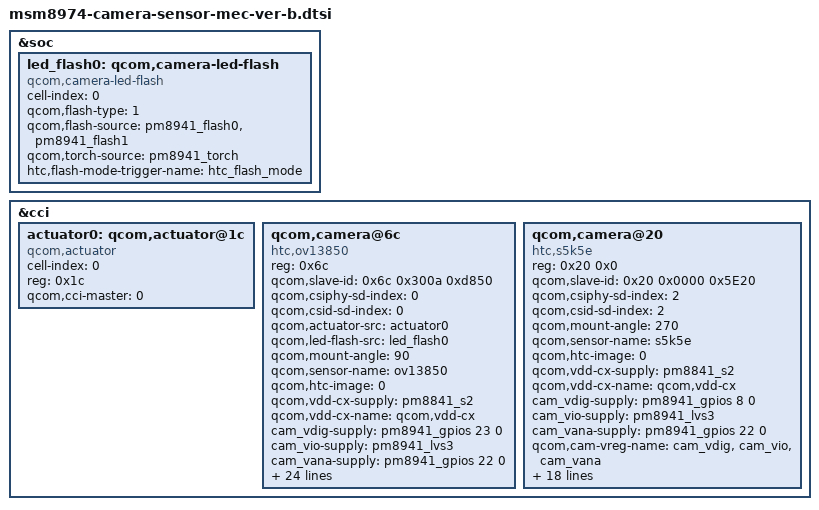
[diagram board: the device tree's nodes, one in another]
/*
 * Copyright (c) 2012-2013, The Linux Foundation. All rights reserved.
 *
 * This program is free software; you can redistribute it and/or modify
 * it under the terms of the GNU General Public License version 2 and
 * only version 2 as published by the Free Software Foundation.
 *
 * This program is distributed in the hope that it will be useful,
 * but WITHOUT ANY WARRANTY; without even the implied warranty of
 * MERCHANTABILITY or FITNESS FOR A PARTICULAR PURPOSE.  See the
 * GNU General Public License for more details.
 */

&soc {

	led_flash0: qcom,camera-led-flash {
		cell-index = <0>;
		compatible = "qcom,camera-led-flash";
		qcom,flash-type = <1>;
		qcom,flash-source = <&pm8941_flash0 &pm8941_flash1>;
		qcom,torch-source = <&pm8941_torch>;
                htc,flash-mode-trigger-name = "htc_flash_mode";
	};
};

&cci {
	actuator0: qcom,actuator@1c {
		cell-index = <0>;
		reg = <0x1c>;
		compatible = "qcom,actuator";
		qcom,cci-master = <0>;
	};

	qcom,camera@6c {
		compatible = "htc,ov13850";
		reg = <0x6c>;
		qcom,slave-id = <0x6c 0x300a 0xd850>;
		qcom,csiphy-sd-index = <0>;
		qcom,csid-sd-index = <0>;
		qcom,actuator-src = <&actuator0>;
		qcom,led-flash-src = <&led_flash0>;

		qcom,mount-angle = <90>;
		qcom,sensor-name = "ov13850";
		qcom,htc-image = <0>;
		qcom,vdd-cx-supply = <&pm8841_s2>;
		qcom,vdd-cx-name = "qcom,vdd-cx";
		cam_vdig-supply = <&pm8941_gpios 23 0>;
		cam_vio-supply = <&pm8941_lvs3>;
		cam_vana-supply = <&pm8941_gpios 22 0>;
		cam_vaf-supply = <&msmgpio 90 0>;
		qcom,cam-vreg-name = "cam_vdig", "cam_vio", "cam_vana",
				     "cam_vaf";
		qcom,cam-vreg-type = <2 1 2 2>;
		qcom,cam-vreg-min-voltage = <0 0 0 0>;
		qcom,cam-vreg-max-voltage = <0 0 0 0>;
		qcom,cam-vreg-op-mode = <0 100000 0 0>;
		qcom,cam-vreg-gpios-index = <2 99 5 3>;

		qcom,gpio-no-mux = <0>;
		gpios = <&msmgpio 15 0>,
			<&pm8941_gpios 12 0>,
			<&pm8941_gpios 23 0>,
			<&msmgpio 90 0>,
			<&pm8941_gpios 11 0>,
			<&pm8941_gpios 22 0>;

		qcom,gpio-reset = <1>;
		qcom,gpio-vcm-pwd = <4>;
		qcom,gpio-req-tbl-num = <0 1 2 3 4 5>;
		qcom,gpio-req-tbl-flags = <0 0 0 0 0 0>;
		qcom,gpio-req-tbl-label = "MCLK_CPU",
					  "CAM_PWDN",
					  "V_CAM_D1V2_EN",
					  "CAM_VCM2V85_EN",
					  "VCM_PWD",
					  "CAM_A2V9_EN";

		qcom,csi-lane-assign = <0x4320>;
		qcom,csi-lane-mask = <0x1F>;
		qcom,sensor-position = <0>;
		qcom,sensor-mode = <1>;
		qcom,cci-master = <0>;
		status = "ok";
	};

	qcom,camera@20 {
		compatible = "htc,s5k5e";
		reg = <0x20 0x0>;
		qcom,slave-id = <0x20 0x0000 0x5E20>;
		qcom,csiphy-sd-index = <2>;
		qcom,csid-sd-index = <2>;
		qcom,mount-angle = <270>;
		qcom,sensor-name = "s5k5e";
		qcom,htc-image = <0>;
		qcom,vdd-cx-supply = <&pm8841_s2>;
		qcom,vdd-cx-name = "qcom,vdd-cx";
		cam_vdig-supply = <&pm8941_gpios 8 0>;
		cam_vio-supply = <&pm8941_lvs3>;
		cam_vana-supply = <&pm8941_gpios 22 0>;

		qcom,cam-vreg-name = "cam_vdig", "cam_vio", "cam_vana";
		qcom,cam-vreg-type = <2 1 2>;
		qcom,cam-vreg-min-voltage = <0 0 0>;
		qcom,cam-vreg-max-voltage = <0 0 0>;
		qcom,cam-vreg-op-mode = <0 0 0>;
		qcom,cam-vreg-gpios-index = <2 99 3>;

		qcom,gpio-no-mux = <0>;
		gpios = <&msmgpio 17 0>,
			    <&msmgpio 31 0>,
			    <&pm8941_gpios 8 0>,
			    <&pm8941_gpios 22 0>;
		qcom,gpio-reset = <1>;
		qcom,gpio-req-tbl-num = <0 1 2 3>;
		qcom,gpio-req-tbl-flags = <1 0 0 0>;
		qcom,gpio-req-tbl-label = "CAM2_MCLK_CPU",
					              "CAM2_RST",
					              "V_CAM_D1V2_EN",
					              "CAM_A2V9_EN";

		qcom,csi-lane-assign = <0x4320>;
		qcom,csi-lane-mask = <0x7>;
		qcom,sensor-position = <1>;
		qcom,sensor-mode = <1>;
		qcom,cci-master = <1>;
		status = "ok";
	};
};

